AUTOSAR XML (schema 4-0-3)
package /ComponentTypes
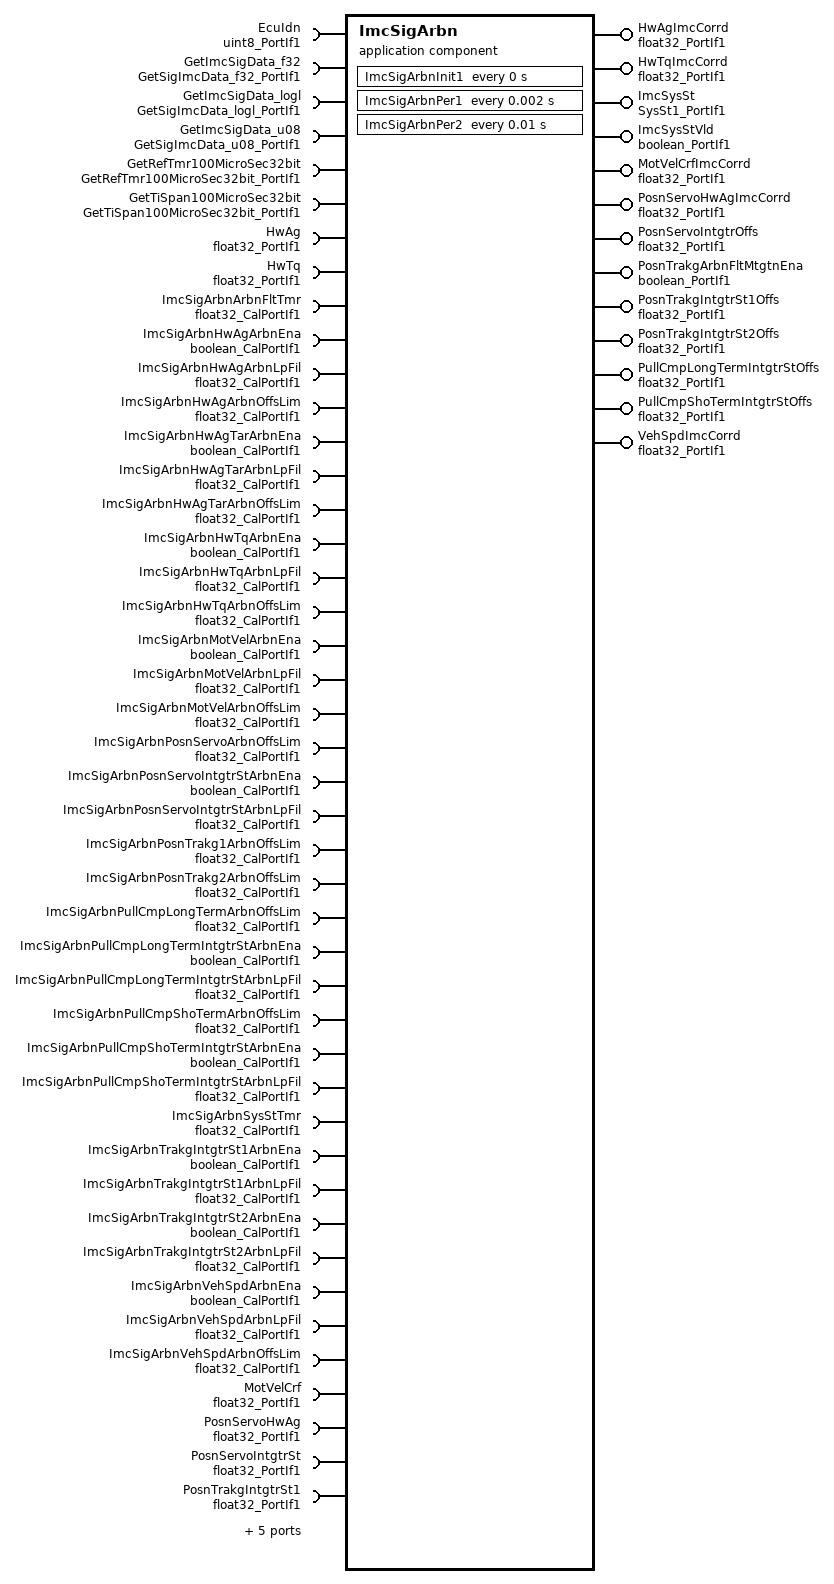
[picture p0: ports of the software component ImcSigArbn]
  application sw component type ImcSigArbn
    13 x provide port:
      HwAgImcCorrd: nonqueued-sender-com-spec{data-element=Val, init-value=0}, provided-interface=float32_PortIf1
      HwTqImcCorrd: nonqueued-sender-com-spec{data-element=Val, init-value=0}, provided-interface=float32_PortIf1
      ImcSysSt: nonqueued-sender-com-spec{data-element=Val, init-value=3}, provided-interface=SysSt1_PortIf1
      ImcSysStVld: nonqueued-sender-com-spec{data-element=Logl, init-value=0}, provided-interface=boolean_PortIf1
      MotVelCrfImcCorrd: nonqueued-sender-com-spec{data-element=Val, init-value=0}, provided-interface=float32_PortIf1
      PosnServoHwAgImcCorrd: nonqueued-sender-com-spec{data-element=Val, init-value=0}, provided-interface=float32_PortIf1
      PosnServoIntgtrOffs: nonqueued-sender-com-spec{data-element=Val, init-value=0}, provided-interface=float32_PortIf1
      PosnTrakgArbnFltMtgtnEna: nonqueued-sender-com-spec{data-element=Logl, init-value=0}, provided-interface=boolean_PortIf1
      PosnTrakgIntgtrSt1Offs: nonqueued-sender-com-spec{data-element=Val, init-value=0}, provided-interface=float32_PortIf1
      PosnTrakgIntgtrSt2Offs: nonqueued-sender-com-spec{data-element=Val, init-value=0}, provided-interface=float32_PortIf1
      PullCmpLongTermIntgtrStOffs: nonqueued-sender-com-spec{data-element=Val, init-value=0}, provided-interface=float32_PortIf1
      PullCmpShoTermIntgtrStOffs: nonqueued-sender-com-spec{data-element=Val, init-value=0}, provided-interface=float32_PortIf1
      VehSpdImcCorrd: nonqueued-sender-com-spec{data-element=Val, init-value=0}, provided-interface=float32_PortIf1
    49 x require port:
      EcuIdn: nonqueued-receiver-com-spec{data-element=Val, filter=data-filter-type=ALWAYS, init-value=0}, required-interface=uint8_PortIf1
      GetImcSigData_f32: client-com-spec=Oper, required-interface=GetSigImcData_f32_PortIf1
      GetImcSigData_logl: client-com-spec=Oper, required-interface=GetSigImcData_logl_PortIf1
      GetImcSigData_u08: client-com-spec=Oper, required-interface=GetSigImcData_u08_PortIf1
      GetRefTmr100MicroSec32bit: client-com-spec=Oper, required-interface=GetRefTmr100MicroSec32bit_PortIf1
      GetTiSpan100MicroSec32bit: client-com-spec=Oper, required-interface=GetTiSpan100MicroSec32bit_PortIf1
      HwAg: nonqueued-receiver-com-spec{data-element=Val, filter=data-filter-type=ALWAYS, init-value=0}, required-interface=float32_PortIf1
      HwTq: nonqueued-receiver-com-spec{data-element=Val, filter=data-filter-type=ALWAYS, init-value=0}, required-interface=float32_PortIf1
      ImcSigArbnArbnFltTmr: parameter-require-com-spec{init-value=20, parameter=Val}, required-interface=float32_CalPortIf1
      ImcSigArbnHwAgArbnEna: parameter-require-com-spec{init-value=1, parameter=Logl}, required-interface=boolean_CalPortIf1
      ImcSigArbnHwAgArbnLpFil: parameter-require-com-spec{init-value=5, parameter=Val}, required-interface=float32_CalPortIf1
      ImcSigArbnHwAgArbnOffsLim: parameter-require-com-spec{init-value=100, parameter=Val}, required-interface=float32_CalPortIf1
      ImcSigArbnHwAgTarArbnEna: parameter-require-com-spec{init-value=1, parameter=Logl}, required-interface=boolean_CalPortIf1
      ImcSigArbnHwAgTarArbnLpFil: parameter-require-com-spec{init-value=5, parameter=Val}, required-interface=float32_CalPortIf1
      ImcSigArbnHwAgTarArbnOffsLim: parameter-require-com-spec{init-value=100, parameter=Val}, required-interface=float32_CalPortIf1
      ImcSigArbnHwTqArbnEna: parameter-require-com-spec{init-value=1, parameter=Logl}, required-interface=boolean_CalPortIf1
      ImcSigArbnHwTqArbnLpFil: parameter-require-com-spec{init-value=5, parameter=Val}, required-interface=float32_CalPortIf1
      ImcSigArbnHwTqArbnOffsLim: parameter-require-com-spec{init-value=20, parameter=Val}, required-interface=float32_CalPortIf1
      ImcSigArbnMotVelArbnEna: parameter-require-com-spec{init-value=1, parameter=Logl}, required-interface=boolean_CalPortIf1
      ImcSigArbnMotVelArbnLpFil: parameter-require-com-spec{init-value=5, parameter=Val}, required-interface=float32_CalPortIf1
      ImcSigArbnMotVelArbnOffsLim: parameter-require-com-spec{init-value=50, parameter=Val}, required-interface=float32_CalPortIf1
      ImcSigArbnPosnServoArbnOffsLim: parameter-require-com-spec{init-value=2, parameter=Val}, required-interface=float32_CalPortIf1
      ImcSigArbnPosnServoIntgtrStArbnEna: parameter-require-com-spec{init-value=1, parameter=Logl}, required-interface=boolean_CalPortIf1
      ImcSigArbnPosnServoIntgtrStArbnLpFil: parameter-require-com-spec{init-value=5, parameter=Val}, required-interface=float32_CalPortIf1
      ImcSigArbnPosnTrakg1ArbnOffsLim: parameter-require-com-spec{init-value=200, parameter=Val}, required-interface=float32_CalPortIf1
      ImcSigArbnPosnTrakg2ArbnOffsLim: parameter-require-com-spec{init-value=3000, parameter=Val}, required-interface=float32_CalPortIf1
      ImcSigArbnPullCmpLongTermArbnOffsLim: parameter-require-com-spec{init-value=8, parameter=Val}, required-interface=float32_CalPortIf1
      ImcSigArbnPullCmpLongTermIntgtrStArbnEna: parameter-require-com-spec{init-value=1, parameter=Logl}, required-interface=boolean_CalPortIf1
      ImcSigArbnPullCmpLongTermIntgtrStArbnLpFil: parameter-require-com-spec{init-value=5, parameter=Val}, required-interface=float32_CalPortIf1
      ImcSigArbnPullCmpShoTermArbnOffsLim: parameter-require-com-spec{init-value=8, parameter=Val}, required-interface=float32_CalPortIf1
      ImcSigArbnPullCmpShoTermIntgtrStArbnEna: parameter-require-com-spec{init-value=1, parameter=Logl}, required-interface=boolean_CalPortIf1
      ImcSigArbnPullCmpShoTermIntgtrStArbnLpFil: parameter-require-com-spec{init-value=5, parameter=Val}, required-interface=float32_CalPortIf1
      ImcSigArbnSysStTmr: parameter-require-com-spec{init-value=20, parameter=Val}, required-interface=float32_CalPortIf1
      ImcSigArbnTrakgIntgtrSt1ArbnEna: parameter-require-com-spec{init-value=1, parameter=Logl}, required-interface=boolean_CalPortIf1
      ImcSigArbnTrakgIntgtrSt1ArbnLpFil: parameter-require-com-spec{init-value=5, parameter=Val}, required-interface=float32_CalPortIf1
      ImcSigArbnTrakgIntgtrSt2ArbnEna: parameter-require-com-spec{init-value=1, parameter=Logl}, required-interface=boolean_CalPortIf1
      ImcSigArbnTrakgIntgtrSt2ArbnLpFil: parameter-require-com-spec{init-value=5, parameter=Val}, required-interface=float32_CalPortIf1
      ImcSigArbnVehSpdArbnEna: parameter-require-com-spec{init-value=1, parameter=Logl}, required-interface=boolean_CalPortIf1
      ImcSigArbnVehSpdArbnLpFil: parameter-require-com-spec{init-value=5, parameter=Val}, required-interface=float32_CalPortIf1
      ImcSigArbnVehSpdArbnOffsLim: parameter-require-com-spec{init-value=20, parameter=Val}, required-interface=float32_CalPortIf1
      MotVelCrf: nonqueued-receiver-com-spec{data-element=Val, filter=data-filter-type=ALWAYS, init-value=0}, required-interface=float32_PortIf1
      PosnServoHwAg: nonqueued-receiver-com-spec{data-element=Val, filter=data-filter-type=ALWAYS, init-value=0}, required-interface=float32_PortIf1
      PosnServoIntgtrSt: nonqueued-receiver-com-spec{data-element=Val, filter=data-filter-type=ALWAYS, init-value=0}, required-interface=float32_PortIf1
      PosnTrakgIntgtrSt1: nonqueued-receiver-com-spec{data-element=Val, filter=data-filter-type=ALWAYS, init-value=0}, required-interface=float32_PortIf1
      PosnTrakgIntgtrSt2: nonqueued-receiver-com-spec{data-element=Val, filter=data-filter-type=ALWAYS, init-value=0}, required-interface=float32_PortIf1
      PullCmpLongTermIntgtrSt: nonqueued-receiver-com-spec{data-element=Val, filter=data-filter-type=ALWAYS, init-value=0}, required-interface=float32_PortIf1
      PullCmpShoTermIntgtrSt: nonqueued-receiver-com-spec{data-element=Val, filter=data-filter-type=ALWAYS, init-value=0}, required-interface=float32_PortIf1
      SetNtcSts: client-com-spec=Oper, required-interface=SetNtcSts_PortIf1
      VehSpd: nonqueued-receiver-com-spec{data-element=Val, filter=data-filter-type=ALWAYS, init-value=0}, required-interface=float32_PortIf1
    behavior ImcSigArbn_InternalBehavior
      ar-typed-per-instance-memorys:
        25 x data, all with sw-calibration-access=READ-ONLY:
          ArbnErrPrev: type=boolean
          ArbnFltPrev: type=boolean
          ArbnFltRefTiEnaLrng: type=uint32
          HwAgLpFil: type=FilLpRec1
          HwAgOffsPrev: type=float32
          HwAgTarLpFil: type=FilLpRec1
          HwAgTarOffsPrev: type=float32
          HwTqLpFil: type=FilLpRec1
          HwTqOffsPrev: type=float32
          MotVelCrfOffsPrev: type=float32
          MotVelLpFil: type=FilLpRec1
          PosnServoIntgtrLpFil: type=FilLpRec1
          PosnServoIntgtrOffsPrev: type=float32
          PullCmpLongTermCmpLpFil: type=FilLpRec1
          PullCmpLongTermIntgtrStOffsPrev: type=float32
          PullCmpShoTermCmpLpFil: type=FilLpRec1
          PullCmpShoTermIntgtrStOffsPrev: type=float32
          SysStLrngEnaPrev: type=boolean
          SysStRefTiEnaLrng: type=uint32
          TrakgIntgtrSt1LpFil: type=FilLpRec1
          TrakgIntgtrSt1Offs: type=float32
          TrakgIntgtrSt2LpFil: type=FilLpRec1
          TrakgIntgtrSt2Offs: type=float32
          VehSpdLpFil: type=FilLpRec1
          VehSpdOffsPrev: type=float32
      timing event ImcSigArbn_InitEvent: start-on-event=ImcSigArbnInit1, period=0
      timing event TMT_ImcSigArbnPer1: start-on-event=ImcSigArbnPer1, period=0.002
      timing event TMT_ImcSigArbnPer2: start-on-event=ImcSigArbnPer2, period=0.01
      explicit-inter-runnable-variables:
        7 x data:
          HwAgOffs: type=float32, init-value=0
          HwAgTarOffs: type=float32, init-value=0
          HwTqOffs: type=float32, init-value=0
          ImcSysSt10MilliSec: type=SysSt1, init-value=3
          ImcSysStVld10MilliSec: type=boolean, init-value=0
          MotVelCrfOffs: type=float32, init-value=0
          VehSpdOffs: type=float32, init-value=0
      runnable ImcSigArbnInit1
        sync call SC_SetNtcSts_Oper: operation=SetNtcSts.Oper, timeout=0
      runnable ImcSigArbnPer1
        data-receive-point-by-arguments:
          5 x access:
            REC_HwAg_Val: accessed-variable=HwAg.Val
            REC_HwTq_Val: accessed-variable=HwTq.Val
            REC_MotVelCrf_Val: accessed-variable=MotVelCrf.Val
            REC_PosnServoHwAg_Val: accessed-variable=PosnServoHwAg.Val
            REC_VehSpd_Val: accessed-variable=VehSpd.Val
        data-send-points:
          7 x access:
            SEND_HwAgImcCorrd_Val: accessed-variable=HwAgImcCorrd.Val
            SEND_HwTqImcCorrd_Val: accessed-variable=HwTqImcCorrd.Val
            SEND_ImcSysSt_Val: accessed-variable=ImcSysSt.Val
            SEND_ImcSysStVld_Logl: accessed-variable=ImcSysStVld.Logl
            SEND_MotVelCrfImcCorrd_Val: accessed-variable=MotVelCrfImcCorrd.Val
            SEND_PosnServoHwAgImcCorrd_Val: accessed-variable=PosnServoHwAgImcCorrd.Val
            SEND_VehSpdImcCorrd_Val: accessed-variable=VehSpdImcCorrd.Val
        read-local-variables:
          7 x access:
            READ_HwAgOffs: accessed-variable=HwAgOffs
            READ_HwAgTarOffs: accessed-variable=HwAgTarOffs
            READ_HwTqOffs: accessed-variable=HwTqOffs
            READ_ImcSysSt10MilliSec: accessed-variable=ImcSysSt10MilliSec
            READ_ImcSysStVld10MilliSec: accessed-variable=ImcSysStVld10MilliSec
            READ_MotVelCrfOffs: accessed-variable=MotVelCrfOffs
            READ_VehSpdOffs: accessed-variable=VehSpdOffs
        sync call SC_GetImcSigData_u08_Oper: operation=GetImcSigData_u08.Oper, timeout=0
        sync call SC_GetRefTmr100MicroSec32bit_Oper: operation=GetRefTmr100MicroSec32bit.Oper, timeout=0
        sync call SC_GetTiSpan100MicroSec32bit_Oper: operation=GetTiSpan100MicroSec32bit.Oper, timeout=0
      runnable ImcSigArbnPer2
        data-receive-point-by-arguments:
          11 x access:
            REC_EcuIdn_Val: accessed-variable=EcuIdn.Val
            REC_HwAg_Val: accessed-variable=HwAg.Val
            REC_HwTq_Val: accessed-variable=HwTq.Val
            REC_MotVelCrf_Val: accessed-variable=MotVelCrf.Val
            REC_PosnServoHwAg_Val: accessed-variable=PosnServoHwAg.Val
            REC_PosnServoIntgtrSt_Val: accessed-variable=PosnServoIntgtrSt.Val
            REC_PosnTrakgIntgtrSt1_Val: accessed-variable=PosnTrakgIntgtrSt1.Val
            REC_PosnTrakgIntgtrSt2_Val: accessed-variable=PosnTrakgIntgtrSt2.Val
            REC_PullCmpLongTermIntgtrSt_Val: accessed-variable=PullCmpLongTermIntgtrSt.Val
            REC_PullCmpShoTermIntgtrSt_Val: accessed-variable=PullCmpShoTermIntgtrSt.Val
            REC_VehSpd_Val: accessed-variable=VehSpd.Val
        data-send-points:
          6 x access:
            SEND_PosnServoIntgtrOffs_Val: accessed-variable=PosnServoIntgtrOffs.Val
            SEND_PosnTrakgArbnFltMtgtnEna_Logl: accessed-variable=PosnTrakgArbnFltMtgtnEna.Logl
            SEND_PosnTrakgIntgtrSt1Offs_Val: accessed-variable=PosnTrakgIntgtrSt1Offs.Val
            SEND_PosnTrakgIntgtrSt2Offs_Val: accessed-variable=PosnTrakgIntgtrSt2Offs.Val
            SEND_PullCmpLongTermIntgtrStOffs_Val: accessed-variable=PullCmpLongTermIntgtrStOffs.Val
            SEND_PullCmpShoTermIntgtrStOffs_Val: accessed-variable=PullCmpShoTermIntgtrStOffs.Val
        6 x sync call, all with timeout=0:
          SC_GetImcSigData_f32_Oper: operation=GetImcSigData_f32.Oper
          SC_GetImcSigData_logl_Oper: operation=GetImcSigData_logl.Oper
          SC_GetImcSigData_u08_Oper: operation=GetImcSigData_u08.Oper
          SC_GetRefTmr100MicroSec32bit_Oper: operation=GetRefTmr100MicroSec32bit.Oper
          SC_GetTiSpan100MicroSec32bit_Oper: operation=GetTiSpan100MicroSec32bit.Oper
          SC_SetNtcSts_Oper: operation=SetNtcSts.Oper
        written-local-variables:
          7 x access:
            WRITE_HwAgOffs: accessed-variable=HwAgOffs
            WRITE_HwAgTarOffs: accessed-variable=HwAgTarOffs
            WRITE_HwTqOffs: accessed-variable=HwTqOffs
            WRITE_ImcSysSt10MilliSec: accessed-variable=ImcSysSt10MilliSec
            WRITE_ImcSysStVld10MilliSec: accessed-variable=ImcSysStVld10MilliSec
            WRITE_MotVelCrfOffs: accessed-variable=MotVelCrfOffs
            WRITE_VehSpdOffs: accessed-variable=VehSpdOffs
  swc implementation ImcSigArbn_Implementation: behavior=ImcSigArbn_InternalBehavior
    code-descriptors:
      code Default: artifact-descriptors=autosar-engineering-object={short-label=Default, category=SWSRC}
